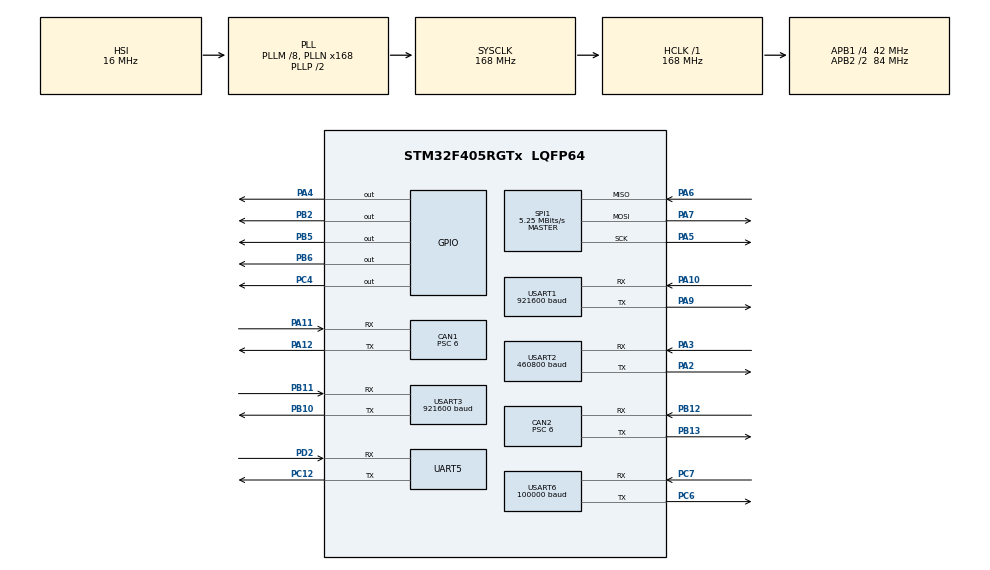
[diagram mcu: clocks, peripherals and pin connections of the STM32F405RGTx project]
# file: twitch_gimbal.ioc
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CAN1.ABOM=ENABLE
CAN1.BS1=CAN_BS1_4TQ
CAN1.BS2=CAN_BS2_2TQ
CAN1.CalculateBaudRate=1000000
CAN1.CalculateTimeBit=1000
CAN1.CalculateTimeQuantum=142.85714285714286
CAN1.NART=ENABLE
CAN1.Prescaler=6
CAN2.ABOM=ENABLE
CAN2.BS1=CAN_BS1_4TQ
CAN2.BS2=CAN_BS2_2TQ
CAN2.CalculateBaudRate=1000000
CAN2.CalculateTimeBit=1000
CAN2.CalculateTimeQuantum=142.85714285714286
CAN2.NART=ENABLE
CAN2.Prescaler=6
Dma.Request0=USART1_RX
Dma.Request1=USART2_RX
Dma.Request2=USART2_TX
Dma.Request3=USART3_RX
Dma.Request4=USART3_TX
Dma.Request5=USART6_RX
Dma.Request6=UART5_RX
Dma.Request7=UART5_TX
Dma.UART5_RX.6.Direction=DMA_PERIPH_TO_MEMORY
Dma.UART5_RX.6.FIFOMode=DMA_FIFOMODE_DISABLE
Dma.UART5_RX.6.Instance=DMA1_Stream0
Dma.UART5_RX.6.MemDataAlignment=DMA_MDATAALIGN_BYTE
Dma.UART5_RX.6.MemInc=DMA_MINC_ENABLE
Dma.UART5_RX.6.Mode=DMA_NORMAL
Dma.UART5_RX.6.PeriphDataAlignment=DMA_PDATAALIGN_BYTE
Dma.UART5_RX.6.PeriphInc=DMA_PINC_DISABLE
Dma.UART5_RX.6.Priority=DMA_PRIORITY_LOW
Dma.UART5_TX.7.Direction=DMA_MEMORY_TO_PERIPH
Dma.UART5_TX.7.FIFOMode=DMA_FIFOMODE_DISABLE
Dma.UART5_TX.7.Instance=DMA1_Stream7
Dma.UART5_TX.7.MemDataAlignment=DMA_MDATAALIGN_BYTE
Dma.UART5_TX.7.MemInc=DMA_MINC_ENABLE
Dma.UART5_TX.7.Mode=DMA_NORMAL
Dma.UART5_TX.7.PeriphDataAlignment=DMA_PDATAALIGN_BYTE
Dma.UART5_TX.7.PeriphInc=DMA_PINC_DISABLE
Dma.UART5_TX.7.Priority=DMA_PRIORITY_LOW
Dma.USART1_RX.0.Direction=DMA_PERIPH_TO_MEMORY
Dma.USART1_RX.0.FIFOMode=DMA_FIFOMODE_DISABLE
Dma.USART1_RX.0.Instance=DMA2_Stream2
Dma.USART1_RX.0.MemDataAlignment=DMA_MDATAALIGN_BYTE
Dma.USART1_RX.0.MemInc=DMA_MINC_ENABLE
Dma.USART1_RX.0.Mode=DMA_NORMAL
Dma.USART1_RX.0.PeriphDataAlignment=DMA_PDATAALIGN_BYTE
Dma.USART1_RX.0.PeriphInc=DMA_PINC_DISABLE
Dma.USART1_RX.0.Priority=DMA_PRIORITY_VERY_HIGH
Dma.USART2_RX.1.Direction=DMA_PERIPH_TO_MEMORY
Dma.USART2_RX.1.FIFOMode=DMA_FIFOMODE_DISABLE
Dma.USART2_RX.1.Instance=DMA1_Stream5
Dma.USART2_RX.1.MemDataAlignment=DMA_MDATAALIGN_BYTE
Dma.USART2_RX.1.MemInc=DMA_MINC_ENABLE
Dma.USART2_RX.1.Mode=DMA_NORMAL
Dma.USART2_RX.1.PeriphDataAlignment=DMA_PDATAALIGN_BYTE
Dma.USART2_RX.1.PeriphInc=DMA_PINC_DISABLE
Dma.USART2_RX.1.Priority=DMA_PRIORITY_VERY_HIGH
Dma.USART2_TX.2.Direction=DMA_MEMORY_TO_PERIPH
Dma.USART2_TX.2.FIFOMode=DMA_FIFOMODE_DISABLE
Dma.USART2_TX.2.Instance=DMA1_Stream6
Dma.USART2_TX.2.MemDataAlignment=DMA_MDATAALIGN_BYTE
Dma.USART2_TX.2.MemInc=DMA_MINC_ENABLE
Dma.USART2_TX.2.Mode=DMA_NORMAL
Dma.USART2_TX.2.PeriphDataAlignment=DMA_PDATAALIGN_BYTE
Dma.USART2_TX.2.PeriphInc=DMA_PINC_DISABLE
Dma.USART2_TX.2.Priority=DMA_PRIORITY_VERY_HIGH
Dma.USART3_RX.3.Direction=DMA_PERIPH_TO_MEMORY
Dma.USART3_RX.3.FIFOMode=DMA_FIFOMODE_DISABLE
Dma.USART3_RX.3.Instance=DMA1_Stream1
Dma.USART3_RX.3.MemDataAlignment=DMA_MDATAALIGN_BYTE
Dma.USART3_RX.3.MemInc=DMA_MINC_ENABLE
Dma.USART3_RX.3.Mode=DMA_NORMAL
Dma.USART3_RX.3.PeriphDataAlignment=DMA_PDATAALIGN_BYTE
Dma.USART3_RX.3.PeriphInc=DMA_PINC_DISABLE
Dma.USART3_RX.3.Priority=DMA_PRIORITY_LOW
Dma.USART3_TX.4.Direction=DMA_MEMORY_TO_PERIPH
Dma.USART3_TX.4.FIFOMode=DMA_FIFOMODE_DISABLE
Dma.USART3_TX.4.Instance=DMA1_Stream3
Dma.USART3_TX.4.MemDataAlignment=DMA_MDATAALIGN_BYTE
Dma.USART3_TX.4.MemInc=DMA_MINC_ENABLE
Dma.USART3_TX.4.Mode=DMA_NORMAL
Dma.USART3_TX.4.PeriphDataAlignment=DMA_PDATAALIGN_BYTE
Dma.USART3_TX.4.PeriphInc=DMA_PINC_DISABLE
Dma.USART3_TX.4.Priority=DMA_PRIORITY_LOW
Dma.USART6_RX.5.Direction=DMA_PERIPH_TO_MEMORY
Dma.USART6_RX.5.FIFOMode=DMA_FIFOMODE_DISABLE
Dma.USART6_RX.5.Instance=DMA2_Stream1
Dma.USART6_RX.5.MemDataAlignment=DMA_MDATAALIGN_BYTE
Dma.USART6_RX.5.MemInc=DMA_MINC_ENABLE
Dma.USART6_RX.5.Mode=DMA_NORMAL
Dma.USART6_RX.5.PeriphDataAlignment=DMA_PDATAALIGN_BYTE
Dma.USART6_RX.5.PeriphInc=DMA_PINC_DISABLE
Dma.USART6_RX.5.Priority=DMA_PRIORITY_LOW
Mcu.Family=STM32F4
Mcu.Name=STM32F405RGTx
Mcu.Package=LQFP64
NVIC.CAN1_RX0_IRQn=true\:0\:0\:false\:false\:true\:true\:true\:true
NVIC.CAN2_RX1_IRQn=true\:0\:0\:false\:false\:true\:true\:true\:true
NVIC.DMA1_Stream0_IRQn=true\:0\:0\:false\:false\:true\:false\:true\:true
NVIC.DMA1_Stream1_IRQn=true\:0\:0\:false\:false\:true\:false\:true\:true
NVIC.DMA1_Stream3_IRQn=true\:0\:0\:false\:false\:true\:false\:true\:true
NVIC.DMA1_Stream5_IRQn=true\:0\:0\:false\:false\:true\:false\:true\:true
NVIC.DMA1_Stream6_IRQn=true\:0\:0\:false\:false\:true\:false\:true\:true
NVIC.DMA1_Stream7_IRQn=true\:0\:0\:false\:false\:true\:false\:true\:true
NVIC.DMA2_Stream1_IRQn=true\:0\:0\:false\:false\:true\:false\:true\:true
NVIC.DMA2_Stream2_IRQn=true\:0\:0\:false\:false\:true\:false\:true\:true
NVIC.PriorityGroup=NVIC_PRIORITYGROUP_4
NVIC.TIM1_UP_TIM10_IRQn=true\:0\:0\:false\:false\:true\:true\:true\:true
NVIC.TIM2_IRQn=true\:0\:0\:false\:false\:true\:true\:true\:true
NVIC.TIM5_IRQn=true\:0\:0\:false\:false\:true\:true\:true\:true
NVIC.TIM6_DAC_IRQn=true\:0\:0\:false\:false\:true\:true\:true\:true
NVIC.TIM7_IRQn=true\:0\:0\:false\:false\:true\:true\:true\:true
NVIC.TIM8_BRK_TIM12_IRQn=true\:0\:0\:false\:false\:true\:true\:true\:true
NVIC.TIM8_UP_TIM13_IRQn=true\:0\:0\:false\:false\:true\:true\:true\:true
NVIC.UART5_IRQn=true\:0\:0\:false\:false\:true\:true\:true\:true
NVIC.USART1_IRQn=true\:0\:0\:false\:false\:true\:true\:true\:true
NVIC.USART2_IRQn=true\:0\:0\:false\:false\:true\:true\:true\:true
NVIC.USART3_IRQn=true\:0\:0\:false\:false\:true\:true\:true\:true
NVIC.USART6_IRQn=true\:0\:0\:false\:false\:true\:true\:true\:true
PA10.GPIO_PuPd=GPIO_PULLUP
PA10.Mode=Asynchronous
PA10.Signal=USART1_RX
PA11.Mode=CAN_Activate
PA11.Signal=CAN1_RX
PA12.Mode=CAN_Activate
PA12.Signal=CAN1_TX
PA13.Mode=Serial_Wire
PA13.Signal=SYS_JTMS-SWDIO
PA14.Mode=Serial_Wire
PA14.Signal=SYS_JTCK-SWCLK
PA2.GPIO_PuPd=GPIO_PULLUP
PA2.Mode=Asynchronous
PA2.Signal=USART2_TX
PA3.GPIO_PuPd=GPIO_PULLUP
PA3.Mode=Asynchronous
PA3.Signal=USART2_RX
PA4.GPIO_PuPd=GPIO_NOPULL
PA4.GPIO_Speed=GPIO_SPEED_FREQ_VERY_HIGH
PA4.PinState=GPIO_PIN_RESET
PA4.Signal=GPIO_Output
PA5.Mode=Full_Duplex_Master
PA5.Signal=SPI1_SCK
PA6.Mode=Full_Duplex_Master
PA6.Signal=SPI1_MISO
PA7.Mode=Full_Duplex_Master
PA7.Signal=SPI1_MOSI
PA9.GPIO_PuPd=GPIO_PULLUP
PA9.Mode=Asynchronous
PA9.Signal=USART1_TX
PB10.GPIO_PuPd=GPIO_PULLUP
PB10.Mode=Asynchronous
PB10.Signal=USART3_TX
PB11.GPIO_PuPd=GPIO_PULLUP
PB11.Mode=Asynchronous
PB11.Signal=USART3_RX
PB12.Mode=CAN_Activate
PB12.Signal=CAN2_RX
PB13.Mode=CAN_Activate
PB13.Signal=CAN2_TX
PB2.GPIO_PuPd=GPIO_NOPULL
PB2.Signal=GPIO_Output
PB5.GPIO_PuPd=GPIO_NOPULL
PB5.Signal=GPIO_Output
PB6.GPIO_PuPd=GPIO_NOPULL
PB6.Signal=GPIO_Output
PC12.Mode=Asynchronous
PC12.Signal=UART5_TX
PC4.GPIO_PuPd=GPIO_NOPULL
PC4.GPIO_Speed=GPIO_SPEED_FREQ_VERY_HIGH
PC4.Signal=GPIO_Output
PC6.GPIO_PuPd=GPIO_PULLUP
PC6.Mode=Asynchronous
PC6.Signal=USART6_TX
PC7.GPIO_PuPd=GPIO_PULLUP
PC7.Mode=Asynchronous
PC7.Signal=USART6_RX
PD2.Mode=Asynchronous
PD2.Signal=UART5_RX
PH0-OSC_IN.Mode=HSE-External-Oscillator
PH0-OSC_IN.Signal=RCC_OSC_IN
PH1-OSC_OUT.Mode=HSE-External-Oscillator
PH1-OSC_OUT.Signal=RCC_OSC_OUT
ProjectManager.HeapSize=0x3C00
ProjectManager.StackSize=0x1000
ProjectManager.TargetToolchain=CMake
RCC.48MHZClocksFreq_Value=84000000
RCC.AHBFreq_Value=168000000
RCC.APB1CLKDivider=RCC_HCLK_DIV4
RCC.APB1Freq_Value=42000000
RCC.APB1TimFreq_Value=84000000
RCC.APB2CLKDivider=RCC_HCLK_DIV2
RCC.APB2Freq_Value=84000000
RCC.APB2TimFreq_Value=168000000
RCC.CortexFreq_Value=168000000
RCC.HCLKFreq_Value=168000000
RCC.HSE_VALUE=25000000
RCC.HSI_VALUE=16000000
RCC.LSE_VALUE=32768
RCC.PLLM=8
RCC.PLLN=168
RCC.SYSCLKFreq_VALUE=168000000
RCC.SYSCLKSource=RCC_SYSCLKSOURCE_PLLCLK
RCC.VCOOutputFreq_Value=336000000
SPI1.BaudRatePrescaler=SPI_BAUDRATEPRESCALER_16
SPI1.CalculateBaudRate=5.25 MBits/s
SPI1.Direction=SPI_DIRECTION_2LINES
SPI1.Mode=SPI_MODE_MASTER
SPI1.VirtualType=VM_MASTER
TIM1.Period=4000-1
TIM1.Prescaler=84-1
TIM2.Period=500-1
TIM2.Prescaler=84-1
TIM5.Period=1000-1
TIM5.Prescaler=84-1
TIM6.Period=10000-1
TIM6.Prescaler=840-1
TIM7.Period=1000-1
TIM7.Prescaler=84-1
TIM8.Period=1250-1
TIM8.Prescaler=84-1
UART5.VirtualMode=Asynchronous
USART1.BaudRate=921600
USART1.VirtualMode=VM_ASYNC
USART2.BaudRate=460800
USART2.VirtualMode=VM_ASYNC
USART3.BaudRate=921600
USART3.VirtualMode=VM_ASYNC
USART6.BaudRate=100000
USART6.Parity=PARITY_EVEN
USART6.VirtualMode=VM_ASYNC
USART6.WordLength=WORDLENGTH_9B
VP_TIM1_VS_ClockSourceINT.Mode=Internal
VP_TIM2_VS_ClockSourceINT.Mode=Internal
VP_TIM5_VS_ClockSourceINT.Mode=Internal
VP_TIM6_VS_ClockSourceINT.Mode=Enable_Timer
VP_TIM7_VS_ClockSourceINT.Mode=Enable_Timer
VP_TIM8_VS_ClockSourceINT.Mode=Internal
board=custom

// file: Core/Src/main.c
/* USER CODE BEGIN Header */
/**
  ******************************************************************************
  * @file           : main.c
  * @brief          : Main program body
  ******************************************************************************
  * @attention
  *
  * Copyright (c) 2026 STMicroelectronics.
  * All rights reserved.
  *
  * This software is licensed under terms that can be found in the LICENSE file
  * in the root directory of this software component.
  * If no LICENSE file comes with this software, it is provided AS-IS.
  *
  ******************************************************************************
  */
/* USER CODE END Header */
#include "main.h"
#include "can.h"
#include "dma.h"
#include "spi.h"
#include "tim.h"
#include "usart.h"
#include "gpio.h"

/* USER CODE BEGIN Includes */
#include "app_gimbal.h"

/* USER CODE END Includes */

void SystemClock_Config(void);

#ifdef AAA
int main(void)
{

  /* MCU Configuration--------------------------------------------------------*/

  /* Reset of all peripherals, Initializes the Flash interface and the Systick. */
  HAL_Init();

  /* Configure the system clock */
  SystemClock_Config();

  /* Initialize all configured peripherals */
  MX_GPIO_Init();
  MX_DMA_Init();
  MX_CAN1_Init();
  MX_CAN2_Init();
  MX_SPI1_Init();
  MX_USART1_UART_Init();
  MX_USART2_UART_Init();
  MX_USART3_UART_Init();
  MX_USART6_UART_Init();
  MX_TIM1_Init();
  MX_TIM5_Init();
  MX_TIM6_Init();
  MX_TIM7_Init();
  MX_TIM8_Init();
  MX_UART5_Init();
  MX_TIM2_Init();

  /* Infinite loop */
  while (1)
  {

  }
}
#endif
void SystemClock_Config(void)
{
  RCC_OscInitTypeDef RCC_OscInitStruct = {0};
  RCC_ClkInitTypeDef RCC_ClkInitStruct = {0};

  /** Configure the main internal regulator output voltage
  */
  __HAL_RCC_PWR_CLK_ENABLE();
  __HAL_PWR_VOLTAGESCALING_CONFIG(PWR_REGULATOR_VOLTAGE_SCALE1);

  /** Initializes the RCC Oscillators according to the specified parameters
  * in the RCC_OscInitTypeDef structure.
  */
  RCC_OscInitStruct.OscillatorType = RCC_OSCILLATORTYPE_HSI;
  RCC_OscInitStruct.HSIState = RCC_HSI_ON;
  RCC_OscInitStruct.HSICalibrationValue = RCC_HSICALIBRATION_DEFAULT;
  RCC_OscInitStruct.PLL.PLLState = RCC_PLL_ON;
  RCC_OscInitStruct.PLL.PLLSource = RCC_PLLSOURCE_HSI;
  RCC_OscInitStruct.PLL.PLLM = 8;
  RCC_OscInitStruct.PLL.PLLN = 168;
  RCC_OscInitStruct.PLL.PLLP = RCC_PLLP_DIV2;
  RCC_OscInitStruct.PLL.PLLQ = 4;
  if (HAL_RCC_OscConfig(&RCC_OscInitStruct) != HAL_OK)
  {
    Error_Handler();
  }

  /** Initializes the CPU, AHB and APB buses clocks
  */
  RCC_ClkInitStruct.ClockType = RCC_CLOCKTYPE_HCLK|RCC_CLOCKTYPE_SYSCLK
                              |RCC_CLOCKTYPE_PCLK1|RCC_CLOCKTYPE_PCLK2;
  RCC_ClkInitStruct.SYSCLKSource = RCC_SYSCLKSOURCE_PLLCLK;
  RCC_ClkInitStruct.AHBCLKDivider = RCC_SYSCLK_DIV1;
  RCC_ClkInitStruct.APB1CLKDivider = RCC_HCLK_DIV4;
  RCC_ClkInitStruct.APB2CLKDivider = RCC_HCLK_DIV2;

  if (HAL_RCC_ClockConfig(&RCC_ClkInitStruct, FLASH_LATENCY_5) != HAL_OK)
  {
    Error_Handler();
  }
}

void Error_Handler(void)
{
  __disable_irq();
  while (1)
  {
  }
}
